# PIC18LF1230 register map
Vendor: Microchip
Architecture 18xxxx. Special function registers and configuration words.
Registers are 8-bit, read-write, reset 0x0 unless marked. A register's access mark holds for its fields unless they carry their own. Addresses are absolute, and some are shared; only a register's first bit layout is shown; lines under a group give offsets from that group; [hi:lo] are bit positions; {n}, {i} and the like mark numbered series; 'fields as' and 'values as' point back to an identical list; <NAME> marks a mode.

## Further device data
pins=1: RA0/AN0/INT0/KBI0/CMP0; 2: RA1/AN1/INT1/KBI1; 3: RA4/T0CKI/AN2/Vref+; 4: MCLR/Vpp/RA5/FLTA; 5: Vss/Avss; 6: RA2/TX/CK; 7: RA3/RX/DT; 8: RB0/PWM0; 9: RB1/PWM1; 10: RB4/PWM2; 11: RB5/PWM3; 12: RB6/PWM4/PGC; 13: RB7/PWM5/PGD; 14: Vdd/Avdd; 15: RA6/OSC2/CLKO/T1OSO/T1CKI/AN3; 16: RA7/OSC1/CLKI/T1OSI/FLTA; 17: RB2/INT2/KBI2/CMP2/T1OSO/T1CKI; 18: RB3/INT3/KBI3/CMP1/T1OSI

## SFR
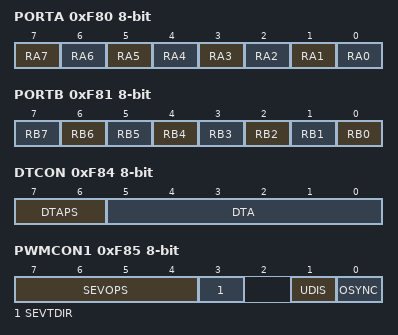
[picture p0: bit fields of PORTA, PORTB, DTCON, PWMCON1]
0xF80 PORTA
  [7] RA7, [6] RA6, [5] RA5 ro, [n] RA{n} (n=0..4)
0xF81 PORTB reset not defined — (power-on value xxxxxxxx)
  [n] RB{n} (n=0..7)
0xF82 OVDCONS
  [5:0] POUT
0xF83 OVDCOND reset 0x3F
  [5:0] POVD
0xF84 DTCON
  [7:6] DTAPS, [5:0] DTA
0xF85 PWMCON1
  [7:4] SEVOPS, [3] SEVTDIR, [1] UDIS, [0] OSYNC
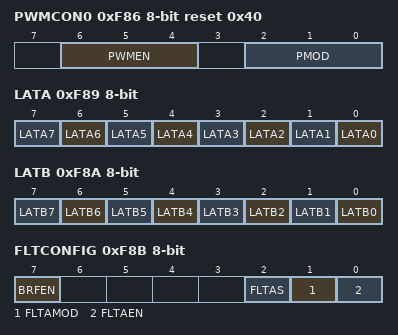
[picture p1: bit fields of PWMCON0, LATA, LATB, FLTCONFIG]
0xF86 PWMCON0 reset 0x40
  [6:4] PWMEN, [2:0] PMOD
0xF87 SEVTCMPH
  [3:0] SEVTCMPH
0xF88 SEVTCMPL
0xF89 LATA reset not defined — (power-on value xxxxxxxx)
  [n] LATA{n} (n=0..7)
0xF8A LATB reset not defined — (power-on value xxxxxxxx)
  [n] LATB{n} (n=0..7)
0xF8B FLTCONFIG
  [7] BRFEN, [2] FLTAS, [1] FLTAMOD, [0] FLTAEN
0xF8C PDC2H
  [5:0] PDC2H
0xF8D PDC2L
0xF8E PDC1H
  [5:0] PDC1H
0xF8F PDC1L
0xF90 PDC0H
  [5:0] PDC0H
0xF91 PDC0L
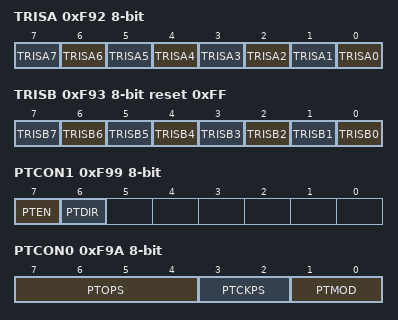
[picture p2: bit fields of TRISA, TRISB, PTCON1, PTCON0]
0xF92 TRISA reset not defined — (power-on value 11x11111)
  [n] TRISA{n} (n=0..7)
0xF93 TRISB reset 0xFF
  [n] TRISB{n} (n=0..7)
0xF95 PTPERH reset 0xF
  [3:0] PTPERH
0xF96 PTPERL reset 0xFF
0xF97 PTMRH
  [3:0] PTMRH
0xF98 PTMRL
0xF99 PTCON1
  [7] PTEN, [6] PTDIR
0xF9A PTCON0
  [7:4] PTOPS, [3:2] PTCKPS, [1:0] PTMOD
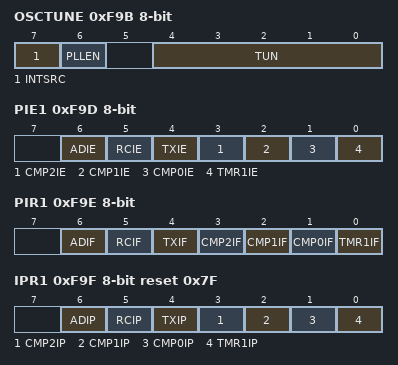
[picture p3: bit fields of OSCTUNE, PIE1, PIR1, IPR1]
0xF9B OSCTUNE
  [7] INTSRC, [6] PLLEN, [4:0] TUN
0xF9D PIE1
  [6] ADIE, [5] RCIE, [4] TXIE, [3] CMP2IE, [2] CMP1IE, [1] CMP0IE, [0] TMR1IE
0xF9E PIR1
  [6] ADIF, [5] RCIF ro, [4] TXIF ro, [3] CMP2IF, [2] CMP1IF, [1] CMP0IF, [0] TMR1IF
0xF9F IPR1 reset 0x7F
  [6] ADIP, [5] RCIP, [4] TXIP, [3] CMP2IP, [2] CMP1IP, [1] CMP0IP, [0] TMR1IP
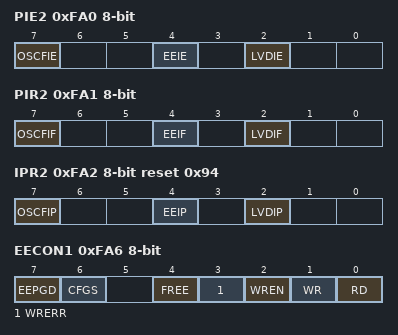
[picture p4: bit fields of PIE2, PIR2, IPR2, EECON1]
0xFA0 PIE2
  [7] OSCFIE, [4] EEIE, [2] LVDIE
0xFA1 PIR2
  [7] OSCFIF, [4] EEIF, [2] LVDIF
0xFA2 IPR2 reset 0x94
  [7] OSCFIP, [4] EEIP, [2] LVDIP
0xFA3 PIE3
  [4] PTIE
0xFA4 PIR3
  [4] PTIF
0xFA5 IPR3 reset 0x10
  [4] PTIP
0xFA6 EECON1 reset not defined — (power-on value xx-0x000)
  [7] EEPGD
  [6] CFGS
  [4] FREE
  [3] WRERR
  [2] WREN
  [1] WR — (can only be set)
  [0] RD — (can only be set)
0xFA7 EECON2 wo reset not defined
0xFA8 EEDATA
0xFA9 EEADR
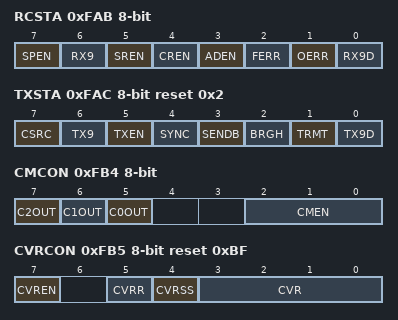
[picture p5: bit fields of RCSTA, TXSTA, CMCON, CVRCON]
0xFAB RCSTA reset not defined — (power-on value 0000000x)
  [7] SPEN, [6] RX9, [5] SREN, [4] CREN, [3] ADEN, [2] FERR ro, [1] OERR ro, [0] RX9D ro
0xFAC TXSTA reset 0x2
  [7] CSRC, [6] TX9, [5] TXEN, [4] SYNC, [3] SENDB, [2] BRGH, [1] TRMT ro, [0] TX9D
0xFAD TXREG wo
0xFAE RCREG ro
0xFAF SPBRG
0xFB0 SPBRGH
0xFB4 CMCON
  [7] C2OUT, [6] C1OUT, [5] C0OUT, [2:0] CMEN
0xFB5 CVRCON reset 0xBF
  [7] CVREN, [5] CVRR, [4] CVRSS, [3:0] CVR
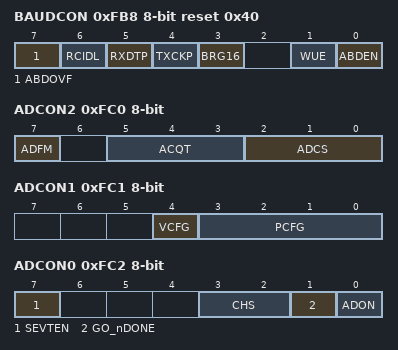
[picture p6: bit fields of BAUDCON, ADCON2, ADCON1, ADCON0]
0xFB8 BAUDCON reset 0x40
  [7] ABDOVF, [6] RCIDL ro, [5] RXDTP, [4] TXCKP, [3] BRG16, [1] WUE, [0] ABDEN
0xFC0 ADCON2
  [7] ADFM, [5:3] ACQT, [2:0] ADCS
0xFC1 ADCON1
  [4] VCFG, [3:0] PCFG
0xFC2 ADCON0
  [7] SEVTEN, [3:2] CHS, [1] GO_nDONE, [0] ADON
0xFC3 ADRESL reset not defined — (power-on value xxxxxxxx)
0xFC4 ADRESH reset not defined — (power-on value xxxxxxxx)
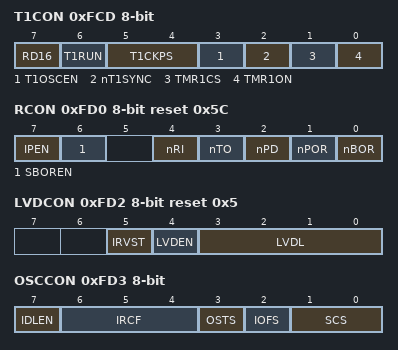
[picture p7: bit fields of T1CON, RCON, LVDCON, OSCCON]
0xFCD T1CON
  [7] RD16, [6] T1RUN ro, [5:4] T1CKPS, [3] T1OSCEN, [2] nT1SYNC, [1] TMR1CS, [0] TMR1ON
0xFCE TMR1L reset not defined — (power-on value xxxxxxxx)
0xFCF TMR1H reset not defined — (power-on value xxxxxxxx)
0xFD0 RCON reset 0x5C
  [7] IPEN, [6] SBOREN, [4] nRI, [3] nTO, [2] nPD, [1] nPOR, [0] nBOR
0xFD1 WDTCON
  [0] SWDTEN
0xFD2 LVDCON reset 0x5
  [5] IRVST, [4] LVDEN, [3:0] LVDL
0xFD3 OSCCON reset not defined — (power-on value 0100q000)
  [7] IDLEN, [6:4] IRCF, [3] OSTS ro, [2] IOFS, [1:0] SCS
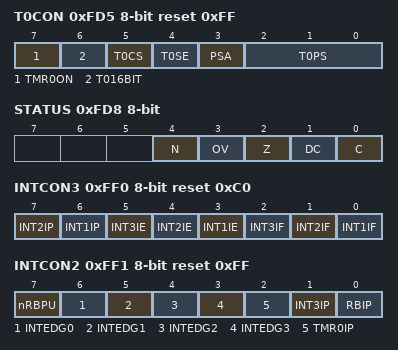
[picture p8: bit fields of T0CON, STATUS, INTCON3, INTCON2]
0xFD5 T0CON reset 0xFF
  [7] TMR0ON, [6] T016BIT, [5] T0CS, [4] T0SE, [3] PSA, [2:0] T0PS
0xFD6 TMR0L reset not defined — (power-on value xxxxxxxx)
0xFD7 TMR0H
0xFD8 STATUS reset not defined — (power-on value ---xxxxx)
  [4] N, [3] OV, [2] Z, [1] DC, [0] C
0xFD9 FSR2L reset not defined — (power-on value xxxxxxxx)
0xFDA FSR2H
  [3:0] FSR2H
0xFDB PLUSW2 access not given reset not defined
0xFDC PREINC2 access not given reset not defined
0xFDD POSTDEC2 access not given reset not defined
0xFDE POSTINC2 access not given reset not defined
0xFDF INDF2 access not given reset not defined
0xFE0 BSR
  [3:0] BSR
0xFE1 FSR1L reset not defined — (power-on value xxxxxxxx)
0xFE2 FSR1H
  [3:0] FSR1H
0xFE3 PLUSW1 access not given reset not defined
0xFE4 PREINC1 access not given reset not defined
0xFE5 POSTDEC1 access not given reset not defined
0xFE6 POSTINC1 access not given reset not defined
0xFE7 INDF1 access not given reset not defined
0xFE8 WREG reset not defined — (power-on value xxxxxxxx)
0xFE9 FSR0L reset not defined — (power-on value xxxxxxxx)
0xFEA FSR0H
  [3:0] FSR0H
0xFEB PLUSW0 access not given reset not defined
0xFEC PREINC0 access not given reset not defined
0xFED POSTDEC0 access not given reset not defined
0xFEE POSTINC0 access not given reset not defined
0xFEF INDF0 access not given reset not defined
0xFF0 INTCON3 reset 0xC0
  [7] INT2IP, [6] INT1IP, [5] INT3IE, [4] INT2IE, [3] INT1IE, [2] INT3IF, [1] INT2IF, [0] INT1IF
0xFF1 INTCON2 reset 0xFF
  [7] nRBPU, [6-n] INTEDG{n} (n=0..3), [2] TMR0IP, [1] INT3IP, [0] RBIP
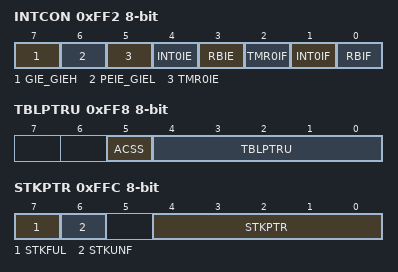
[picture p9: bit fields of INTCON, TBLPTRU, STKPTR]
0xFF2 INTCON reset not defined — (power-on value 0000000x)
  [7] GIE_GIEH, [6] PEIE_GIEL, [5] TMR0IE, [4] INT0IE, [3] RBIE, [2] TMR0IF, [1] INT0IF, [0] RBIF
0xFF3 PRODL reset not defined — (power-on value xxxxxxxx)
0xFF4 PRODH reset not defined — (power-on value xxxxxxxx)
0xFF5 TABLAT
0xFF6 TBLPTRL
0xFF7 TBLPTRH
0xFF8 TBLPTRU
  [5] ACSS, [4:0] TBLPTRU
0xFF9 PCL
0xFFA PCLATH
  [7:0] PCH
0xFFB PCLATU
  [4:0] PCU
0xFFC STKPTR
  [7] STKFUL — (can only be cleared)
  [6] STKUNF — (can only be cleared)
  [4:0] STKPTR
0xFFD TOSL
0xFFE TOSH
0xFFF TOSU
  [4:0] TOSU
